# STM32WB05 register map
File version: 0.3
CPU: CM0+ r0p0, little endian, MPU, no FPU, 4 interrupt priority bits
Registers are 32-bit, read-write, reset 0x0 unless marked. A register's access mark holds for its fields unless they carry their own. Offsets are from the block's base; [hi:lo] are bit positions; {n}, {i} and the like mark numbered series; 'fields as' and 'values as' point back to an identical list.

## ADC
Base 0x41006000
0x00 VERSION_ID ro reset 0x30
  [7:0] VERSION_ID — VERSION_ID[7:0]: version of the embedded IP.
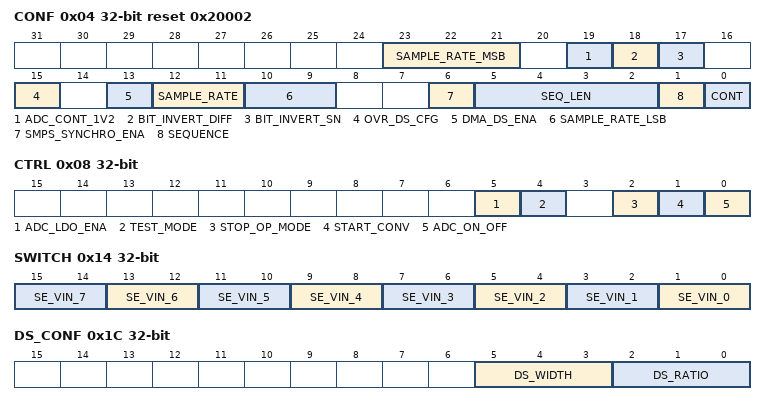
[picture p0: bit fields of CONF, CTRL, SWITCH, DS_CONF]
0x04 CONF reset 0x20002 (reset mask 0xFFFFF)
  [23:21] SAMPLE_RATE_MSB — SAMPLE_RATE_MSB: Sample Rate MSB This field is an extension of SAMPLE_RATE definition in bits 12,11 of CONF register. It impacts the conversion rate of ADC (F_ADC). See SAMPLE_RATE bits for the full description
  [19] ADC_CONT_1V2 — ADC_CONT_1V2: select the input sampling method: 0: sampling only at conversion start (default) 1: sampling starts at the end of conversion
  [18] BIT_INVERT_DIFF — BIT_INVERT_DIFF: invert bit to bit the ADC data output (1's complement) when a differential input is connected to the ADC: 0: no inversion (default) 1: enable the inversion
  [17] BIT_INVERT_SN — BIT_INVERT_SN: invert bit to bit the ADC data output (1's complement) when a single negative input is connected to the ADC: 0: no inversion (default) 1: enable the inversion
  [15] OVR_DS_CFG — OVR_DS_CFG: Down Sampler overrun configuration: 0: the previous data is kept, the new one is lost 1: the previous data is lost, the new one is kept
  [13] DMA_DS_ENA — DMA_DS_EN: enable the DMA mode for the Down Sampler data path: 0: DMA mode is disabled 1: DMA mode is enabled
  [12:11] SAMPLE_RATE — SAMPLE_RATE[1:0]: conversion rate of ADC (F_ADC): F_ADC = F_ADC_CLK/(16 + 16*SAMPLE_RATE_MSB + 4*SAMPLE_RATE + SAMPLE_RATE_LSB),where F_ADC_CLK is the analog ADC clock frequency. By default F_ADC_CLK is 16MHz frequency.
  [10:9] SAMPLE_RATE_LSB — SAMPLE_RATE_LSB: Sample Rate LSB This field is an extension of SAMPLE_RATE definition in bits 12,11 of CONF register. It impacts the conversion rate of ADC (F_ADC). See SAMPLE_RATE bits for the full description. When this field is set to a value different than 0, SMPS synchronization is not feasible. This value is hidden to the user
  [6] SMPS_SYNCHRO_ENA — SMPS_SYNCHRO_ENA: synchronize the ADC start conversion with a pulse generated by the SMPS: 0: SMPS synchronization is disabled for all ADC clock frequencies 1: SMPS synchronization is enabled (only when ADC clock is 8 MHz or 16 MHz) Note: SMPS_SYNCHRO_ENA must be 0 when the ADC analog clock is 32 MHz or when PWRC_CR5.NOSMPS = 1.
  [5:2] SEQ_LEN — SEQ_LEN[3:0]: number of conversions in a regular sequence: 0000: 1 conversion, starting from SEQ0 0001: 2 conversions, starting from SEQ0 ... 1111: 16 conversions, starting from SEQ0
  [1] SEQUENCE — SEQUENCE: enable the sequence mode (active by default): 0: sequence mode is disabled, only SEQ0 is selected 1: sequence mode is enabled, conversions from SEQ0 to SEQx with x=SEQ_LEN Note: clearing this bit is equivalent to SEQUENCE=1 and SEQ_LEN=0000. Ideally, this bit can be kept high as redundant with keeping high and setting SEQ_LEN=0000.
  [0] CONT — CONT: regular sequence runs continuously when ADC mode is enabled: 0: enable the single conversion: when the sequence is over, the conversion stops 1: enable the continuous conversion: when the sequence is over, the sequence starts again until the software sets the CTRL.STOP_OP_MODE bit.
0x08 CTRL (reset mask 0xF)
  [5] ADC_LDO_ENA — ADC_LDO_ENA: enable the LDO associated to the ADC block: 0: disable the ADC LDO 1: enable the ADC LDO
  [4] TEST_MODE — TEST_MODE: select the functional or the test mode of the ADC: 0: functional mode (one of the four main functional modes is used) 1: test mode (for debug, test, calibration)
  [2] STOP_OP_MODE wo — STOP_OP_MODE (1): stop the on-going OP_MODE (ADC mode, Analog audio mode, Full mode): 0: no effect 1: stop on-going ADC mode Note: this bit is set by software and cleared by hardware. When setting the STOP_MODE_OP, the user has to wait around 10 us before to start a new ADC conversion by setting the START_CONV bit.
  [1] START_CONV wo — START_CONV (1): generate a start pulse to initiate an ADC conversion: 0: no effect 1: start the ADC conversion Note: this bit is set by software and cleared by hardware.
  [0] ADC_ON_OFF — ADC_ON_OFF: 0: power off the ADC 1: power on the ADC
0x14 SWITCH (reset mask 0xF)
  [2n+1:2n] SE_VIN_{n} (n=4..7) — SE_VIN_{n}[1:0]: input voltage for VINP[{n-4}] 00: Vinput = 1.2V 01: reserved (not used for this cut) 10: Vinput = 2.4V 11: Vinput = 3.6V
  [2n+1:2n] SE_VIN_{n} (n=0..3) — SE_VIN_{n}[1:0]: input voltage for VINM[{n}] / VINP[{n}]-VINM[{n}] 00: Vinput = 1.2V 01: reserved (not used for this cut) 10: Vinput = 2.4V 11: Vinput = 3.6V
0x1C DS_CONF (reset mask 0xF)
  [5:3] DS_WIDTH — DS_WIDTH[2:0]: program the Down Sampler width of data output (DSDTATA) 000: DS_DATA output on 12-bit (default) 001: DS_DATA output on 13-bit 010: DS_DATA output on 14-bit 011: DS_DATA output on 15-bit 100: DS_DATA output on 16-bit 1xx: reserved
  [2:0] DS_RATIO — DS_RATIO[2:0]: program the Down Sampler ratio (N factor) 000: ratio = 1, no down sampling (default) 001: ratio = 2 010: ratio = 4 011: ratio = 8 100: ratio = 16 101: ratio = 32 110: ratio = 64 111: ratio = 128
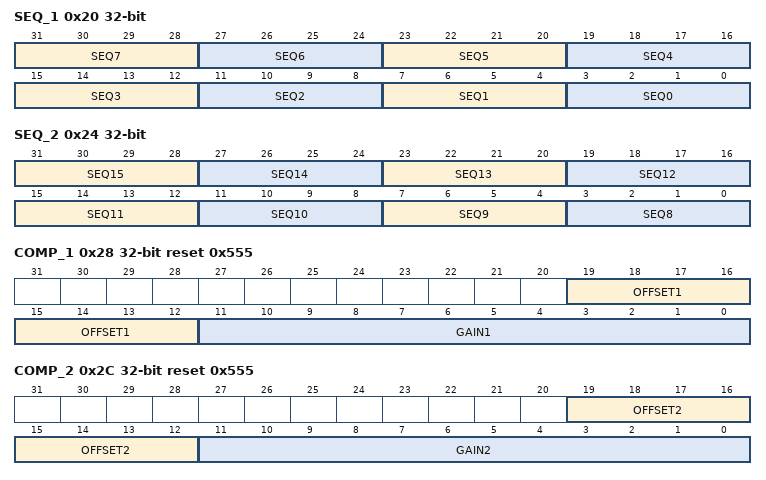
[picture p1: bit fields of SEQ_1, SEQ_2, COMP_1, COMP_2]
0x20 SEQ_1 (reset mask 0xF)
  [4n+3:4n] SEQ{n} (n=3..7) — SEQ{n}[3:0]: channel number code for {n+1}th conversion of the sequence. See SEQ0 for code detail.
  [11:8] SEQ2 — SEQ2[3:0]: channel number code for 3rd conversion of the sequence. See SEQ0 for code detail.
  [7:4] SEQ1 — SEQ1[3:0]: channel number code for second conversion of the sequence. See SEQ0 for code detail.
  [3:0] SEQ0 — SEQ0[3:0]: channel number code for first conversion of the sequence 0000: VINM[0] to ADC single negative input 0001: VINM[1] to ADC single negative input 0010: VINM[2] to ADC single negative input 0011: VINM[3] to ADC single negative input 0100: VINP[0] to ADC single positive input 0101: VINP[1] to ADC single positive input 0110: VINP[2] to ADC single positive input 0111: VINP[3] to ADC single positive input 1000: VINP[0]-VINM[0] to ADC differential input 1001: VINP[1]-VINM[1] to ADC differential input 1010: VINP[2]-VINM[2] to ADC differential input 1011: VINP[3]-VINM[3] to ADC differential input 1100: VBAT - Battery level detector 1101: Temperature sensor 111x: reserved
0x24 SEQ_2 (reset mask 0xF)
  [4n-29:4n-32] SEQ{n} (n=9..15) — SEQ{n}[3:0]: channel number code for {n+1}th conversion of the sequence. See SEQ0 for code detail.
  [3:0] SEQ8 — SEQ8[3:0]: channel number code for 9th conversion of the sequence 0000: VINM[0] to ADC single negative input 0001: VINM[1] to ADC single negative input 0010: VINM[2] to ADC single negative input 0011: VINM[3] to ADC single negative input 0100: VINP[0] to ADC single positive input 0101: VINP[1] to ADC single positive input 0110: VINP[2] to ADC single positive input 0111: VINP[3] to ADC single positive input 1000: VINP[0]-VINM[0] to ADC differential input 1001: VINP[1]-VINM[1] to ADC differential input 1010: VINP[2]-VINM[2] to ADC differential input 1011: VINP[3]-VINM[3] to ADC differential input 1100: VBAT - Battery level detector 1101: Temperature sensor 111x: reserved
0x28 COMP_1 reset 0x555 (reset mask 0xFFF)
  [19:12] OFFSET1 — OFFSET1[7:0]: first calibration point: offset compensation[7:0] with sign
  [11:0] GAIN1 — GAIN1[11:0]: first calibration point: gain AUXADC_GAIN_1V2[11:0]
0x2C COMP_2 reset 0x555 (reset mask 0xFFF)
  [19:12] OFFSET2 — OFFSET2[7:0]: second calibration point: offset compensation[7:0] with sign
  [11:0] GAIN2 — GAIN2[11:0]: second calibration point: gain AUXADC_GAIN_1V2[11:0]
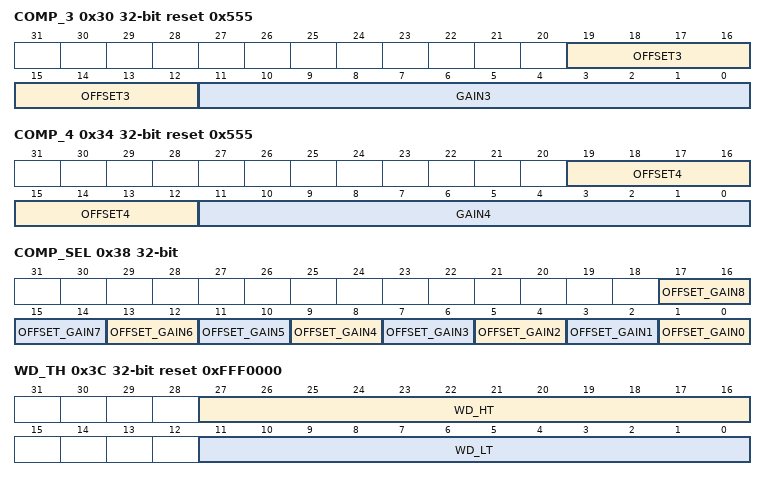
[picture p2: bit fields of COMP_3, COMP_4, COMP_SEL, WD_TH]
0x30 COMP_3 reset 0x555 (reset mask 0xFFF)
  [19:12] OFFSET3 — OFFSET3[7:0]: third calibration point: offset compensation[7:0] with sign
  [11:0] GAIN3 — GAIN3[11:0]: third calibration point: gain AUXADC_GAIN_1V2[11:0]
0x34 COMP_4 reset 0x555 (reset mask 0xFFF)
  [19:12] OFFSET4 — OFFSET4[7:0]: fourth calibration point: offset compensation[7:0] with sign
  [11:0] GAIN4 — GAIN4[11:0]: fourth calibration point: gain AUXADC_GAIN_1V2[11:0]
0x38 COMP_SEL (reset mask 0xF)
  [17:16] OFFSET_GAIN8 — OFFSET_GAIN8[1:0]: gain / offset used in ADC differential mode with Vinput range = 3.6V: 00: OFFSET1 and GAIN1 from COMP_1 01: OFFSET2 and GAIN2 from COMP_2 10: OFFSET3 and GAIN3 from COMP_3 11: OFFSET4 and GAIN4 from COMP_4
  [15:14] OFFSET_GAIN7 — OFFSET_GAIN7[1:0]: gain / offset used in ADC single positive mode with Vinput range = 3.6V: 00: OFFSET1 and GAIN1 from COMP_1 01: OFFSET2 and GAIN2 from COMP_2 10: OFFSET3 and GAIN3 from COMP_3 11: OFFSET4 and GAIN4 from COMP_4
  [13:12] OFFSET_GAIN6 — OFFSET_GAIN6[1:0]: gain / offset used in ADC single negative mode with Vinput range = 3.6V: 00: OFFSET1 and GAIN1 from COMP_1 01: OFFSET2 and GAIN2 from COMP_2 10: OFFSET3 and GAIN3 from COMP_3 11: OFFSET4 and GAIN4 from COMP_4
  [11:10] OFFSET_GAIN5 — OFFSET_GAIN5[1:0]: gain / offset used in ADC differential mode with Vinput range = 2.4V: 00: OFFSET1 and GAIN1 from COMP_1 01: OFFSET2 and GAIN2 from COMP_2 10: OFFSET3 and GAIN3 from COMP_3 11: OFFSET4 and GAIN4 from COMP_4
  [9:8] OFFSET_GAIN4 — OFFSET_GAIN4[1:0]: gain / offset used in ADC single positive mode with Vinput range = 2.4V: 00: OFFSET1 and GAIN1 from COMP_1 01: OFFSET2 and GAIN2 from COMP_2 10: OFFSET3 and GAIN3 from COMP_3 11: OFFSET4 and GAIN4 from COMP_4
  [7:6] OFFSET_GAIN3 — OFFSET_GAIN3[1:0]: gain / offset used in ADC single negative mode with Vinput range = 2.4V: 00: OFFSET1 and GAIN1 from COMP_1 01: OFFSET2 and GAIN2 from COMP_2 10: OFFSET3 and GAIN3 from COMP_3 11: OFFSET4 and GAIN4 from COMP_4
  [5:4] OFFSET_GAIN2 — OFFSET_GAIN2[1:0]: gain / offset used in ADC differential mode with Vinput range = 1.2V: 00: OFFSET1 and GAIN1 from COMP_1 01: OFFSET2 and GAIN2 from COMP_2 10: OFFSET3 and GAIN3 from COMP_3 11: OFFSET4 and GAIN4 from COMP_4
  [3:2] OFFSET_GAIN1 — OFFSET_GAIN1[1:0]: gain / offset used in ADC single positive mode with Vinput range = 1.2V: 00: OFFSET1 and GAIN1 from COMP_1 01: OFFSET2 and GAIN2 from COMP_2 10: OFFSET3 and GAIN3 from COMP_3 11: OFFSET4 and GAIN4 from COMP_4
  [1:0] OFFSET_GAIN0 — OFFSET_GAIN0[1:0]: gain / offset used in ADC single negative mode with Vinput range = 1.2V: 00: OFFSET1 and GAIN1 from COMP_1 01: OFFSET2 and GAIN2 from COMP_2 10: OFFSET3 and GAIN3 from COMP_3 11: OFFSET4 and GAIN4 from COMP_4
0x3C WD_TH reset 0xFFF0000
  [27:16] WD_HT — WD_HT[11:0]: analog watchdog high level threshold.
  [11:0] WD_LT — WD_LT[11:0]: analog watchdog low level threshold.
0x40 WD_CONF (reset mask 0xF)
  [15:0] AWD_CHX — AWD_CHX[15:0]: analog watchdog channel selection to define which input channel(s) need to be guarded by the watchdog. Bit0: VINM[0] to ADC negative input Bit1: VINM[1] to ADC negative input Bit2: VINM[2] to ADC negative input Bit3: VINM[3] to ADC negative input Bit4: Not used Bit5: VBAT to ADC negative input Bit6: GND to ADC negative input Bit7: VDDA to ADC negative input Bit8: VINP[0] to ADC positive input Bit9: VINP[1] to ADC positive input Bit10: VINP[2] to ADC positive input Bit11: VINP[3] to ADC positive input Bit12: Not used Bit13: TEMP to ADC positive input Bit14: GND to ADC positive input Bit15: VDDA to ADC positive input
0x44 DS_DATAOUT ro (reset mask 0xF)
  [15:0] DS_DATA — DS_DATA[15:0]: contain the converted data at the output of the Down Sampler.
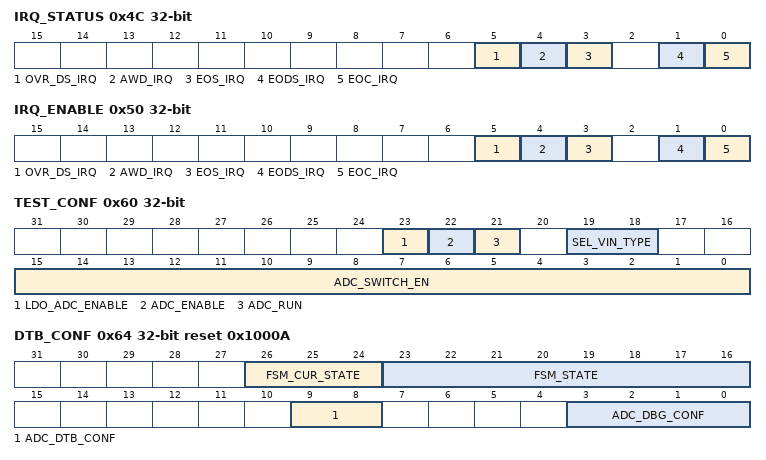
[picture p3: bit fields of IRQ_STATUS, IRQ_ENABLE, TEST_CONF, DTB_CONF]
0x4C IRQ_STATUS (reset mask 0xF)
  [5] OVR_DS_IRQ — OVR_DS_IRQ: set to indicate a Down Sampler overrun (at least one data is lost) When read, provide the status of the interrupt: 0: no overrun occurred 1: overrun occurred Writing this bit clears the status of the interrupt: 0: no effect 1: clear the interrupt
  [4] AWD_IRQ — AWD_IRQ: set when an analog watchdog event occurs. When read, provide the status of the interrupt: 0: no analog watchdog event occurred 1: analog watchdog event has occurred Writing this bit clears the status of the interrupt: 0: no effect 1: clear the interrupt
  [3] EOS_IRQ — EOS_IRQ: set when a sequence of conversion is completed. When read, provide the status of the interrupt: 0: sequence of conversion is not completed 1: sequence of conversion is completed Writing this bit clears the status of the interrupt: 0: no effect 1: clear the interrupt
  [1] EODS_IRQ — EODS_IRQ: set when the Down Sampler conversion is completed. When read, provide the status of the interrupt: 0: Down Sampler conversion is not completed 1: Down Sampler conversion is completed Writing this bit clears the status of the interrupt: 0: no effect 1: clear the interrupt
  [0] EOC_IRQ — EOC_IRQ (Used in test mode only): set when the ADC conversion is completed. When read, provide the status of the interrupt: 0: ADC conversion is not completed 1: ADC conversion is completed Writing this bit clears the status of the interrupt: 0: no effect 1: clear the interrupt
0x50 IRQ_ENABLE (reset mask 0xF)
  fields as IRQ_STATUS
0x54 TIMER_CONF reset 0x28
  [7:0] ADC_LDO_DELAY — ADC_LDO_DELAY[7:0]: define the duration of a waiting time to be inserted between the ADC_LDO enable and the ADC ON to let time to the LDO to stabilize before starting a conversion. The time unit is 4 us. Maximum delay is 1.02 ms (255 x 4 us). Default value is 40 = 160 us.
0x60 TEST_CONF (reset mask 0xF)
  [23] LDO_ADC_ENABLE — LDO_ADC_ENABLE: 0: disable the ADC LDO 1: enable the ADC LDO
  [22] ADC_ENABLE — ADC_ENABLE: 0: disable the ADC (power OFF) 1: enable the ADC (power ON)
  [21] ADC_RUN — ADC_RUN: Start/stop ADC conversion. 0: stop the ADC conversion, 1: starts the ADC conversion.
  [19:18] SEL_VIN_TYPE — SEL_VIN_TYPE[1:0]: operation mode of the selected VIN 00: ADC single negative input 01: ADC single positive input 10: ADC differential input mode 11: reserved
  [15:0] ADC_SWITCH_EN — ADC_SWITCH_EN[15:0]: enable individually each connection of the switching matrix at the ADC input. For each bit: 0: switch X is ON 1: switch X is OFF Bit mapping (corresponding to AUXADC_INSEL_1V2[15:0]): Bit 0: VINM[0] to ADC negative input Bit 1: VINM[1] to ADC negative input Bit 2: VINM[2] to ADC negative input Bit 3: VINM[3] to ADC negative input Bit4: GND to ADC negative input Bit5: VBAT to ADC negative input Bit6: GND to ADC negative input Bit7: VDDA to ADC negative input Bit8: VINP[0] to ADC positive input Bit9: VINP[1] to ADC positive input Bit10: VINP[2] to ADC positive input Bit11: VINP[3] to ADC positive input Bit12: VBAT to ADC positive input Bit13: TEMP to ADC positive input Bit14: GND to ADC positive input Bit15: VDDA to ADC positive input.
0x64 DTB_CONF reset 0x1000A (reset mask 0xFFFFF)
  [26:24] FSM_CUR_STATE ro — FSM_CUR_STATE[2:0]: show the last executed state by the state machine. 000: IDLE mode 001: ADC_LDO setup phase 010: ADC setup phase 011: PGA BIAS setup phase 100: ADC_START_CONV resynchronization 101: Analog Audio mode or Full mode 110: ADC mode or occasional mode 111: sequence mode
  [23:16] FSM_STATE ro — FSM_STATE[7:0]: show the state of the state machine. Bit 0: IDLE Bit 1: ADC_LDO setup phase Bit 2: ADC setup phase Bit 3: PGA BIAS setup phase Bit 4: ADC_START_CONV resynchronization Bit 5: Analog Audio mode or Full mode Bit 6: ADC mode or occasional mode Bit 7: sequence mode
  [9:8] ADC_DTB_CONF — ADC_DTB_CONF[1:0]: configure the DTB output. 00: DTB bus is all 0 01: output the ADC_BUSY, ADC_EOC, offset compensation data[11:0] on the ADC_DTB 10: output the DS information on the ADC_DTB 11: select states of the FSM and enable ADC serial output Note: detailed DTB configurations are available in the Table 38 in IUM
  [3:0] ADC_DBG_CONF — ADC_DBG_CONF[3:0]: use for debug purpose.

## Notices in the file
Copyright (c) 2024 STMicroelectronics.
SPDX-License-Identifier: Apache-2.0
Licensed under the Apache License, Version 2.0 (the "License");
you may not use this file except in compliance with the License.
You may obtain a copy of the License at
http://www.apache.org/licenses/LICENSE-2.0
Unless required by applicable law or agreed to in writing, software
distributed under the License is distributed on an "AS IS" BASIS,
WITHOUT WARRANTIES OR CONDITIONS OF ANY KIND, either express or implied.
See the License for the specific language governing permissions and
limitations under the License.
